# ESP32-H2 register map
Vendor: ESPRESSIF SYSTEMS (SHANGHAI) CO., LTD.; Series: ESP32 H-Series; File version: 11
CPU: RV32IMAC r0p0, little endian, no MPU, no FPU, 0 interrupt priority bits
Address unit: 32 bits
Registers are 32-bit, read-write, reset 0x0 unless marked. A register's access mark holds for its fields unless they carry their own. Offsets are from the block's base; [hi:lo] are bit positions; {n}, {i} and the like mark numbered series.

## GPIO_SD — Sigma-Delta Modulation
Base 0x60091F00
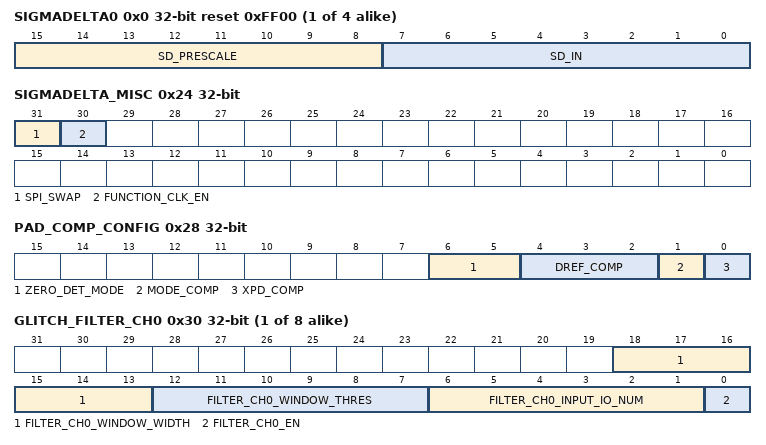
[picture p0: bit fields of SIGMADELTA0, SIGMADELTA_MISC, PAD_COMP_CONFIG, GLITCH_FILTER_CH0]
{0x0+4i} SIGMADELTA{i} (i=0..3) reset 0xFF00 — Duty Cycle Configure Register of SDM{i}
  [15:8] SD_PRESCALE — This field is used to set a divider value to divide APB clock.
  [7:0] SD_IN — This field is used to configure the duty cycle of sigma delta modulation output.
0x20 CLOCK_GATE — Clock Gating Configure Register
  [0] CLK_EN — Clock enable bit of configuration registers for sigma delta modulation.
0x24 SIGMADELTA_MISC — MISC Register
  [31] SPI_SWAP — Reserved.
  [30] FUNCTION_CLK_EN — Clock enable bit of sigma delta modulation.
0x28 PAD_COMP_CONFIG — PAD Compare configure Register
  [6:5] ZERO_DET_MODE — Zero Detect mode select.
  [4:2] DREF_COMP — internal reference voltage tuning bit. 0V to 0.7*VDDPST step 0.1*VDDPST.
  [1] MODE_COMP — 1 to enable external reference from PAD[0]. 0 to enable internal reference, meanwhile PAD[0] can be used as a regular GPIO.
  [0] XPD_COMP — Pad compare enable bit.
0x2C PAD_COMP_FILTER — Zero Detect filter Register
  [31:0] ZERO_DET_FILTER_CNT — Zero Detect filter cycle length
{0x30+4i} GLITCH_FILTER_CH{i} (i=0..7) — Glitch Filter Configure Register of Channel{i}
  [18:13] FILTER_CH0_WINDOW_WIDTH — Glitch Filter window width.
  [12:7] FILTER_CH0_WINDOW_THRES — Glitch Filter window threshold.
  [6:1] FILTER_CH0_INPUT_IO_NUM — Glitch Filter input io number.
  [0] FILTER_CH0_EN — Glitch Filter channel enable bit.
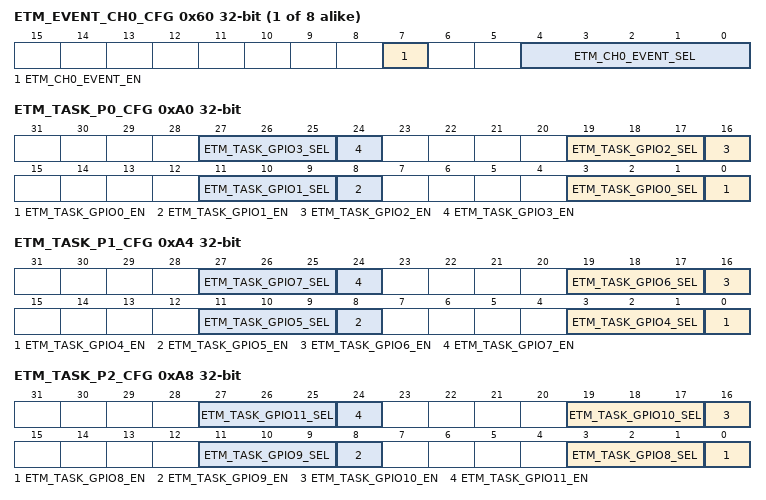
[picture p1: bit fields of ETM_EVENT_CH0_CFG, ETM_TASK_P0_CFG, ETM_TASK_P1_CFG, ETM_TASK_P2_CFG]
{0x60+4i} ETM_EVENT_CH{i}_CFG (i=0..7) — Etm Config register of Channel{i}
  [7] ETM_CH0_EVENT_EN — Etm event send enable bit.
  [4:0] ETM_CH0_EVENT_SEL — Etm event channel select gpio.
0xA0 ETM_TASK_P0_CFG — Etm Configure Register to decide which GPIO been chosen
  [8n+3:8n+1] ETM_TASK_GPIO{n}_SEL (n=0..3) — GPIO choose a etm task channel.
  [8n] ETM_TASK_GPIO{n}_EN (n=0..3) — Enable bit of GPIO response etm task.
0xA4 ETM_TASK_P1_CFG — Etm Configure Register to decide which GPIO been chosen
  [8n-29:8n-31] ETM_TASK_GPIO{n}_SEL (n=4..7) — GPIO choose a etm task channel.
  [8n-32] ETM_TASK_GPIO{n}_EN (n=4..7) — Enable bit of GPIO response etm task.
0xA8 ETM_TASK_P2_CFG — Etm Configure Register to decide which GPIO been chosen
  [8n-61:8n-63] ETM_TASK_GPIO{n}_SEL (n=8..11) — GPIO choose a etm task channel.
  [8n-64] ETM_TASK_GPIO{n}_EN (n=8..11) — Enable bit of GPIO response etm task.
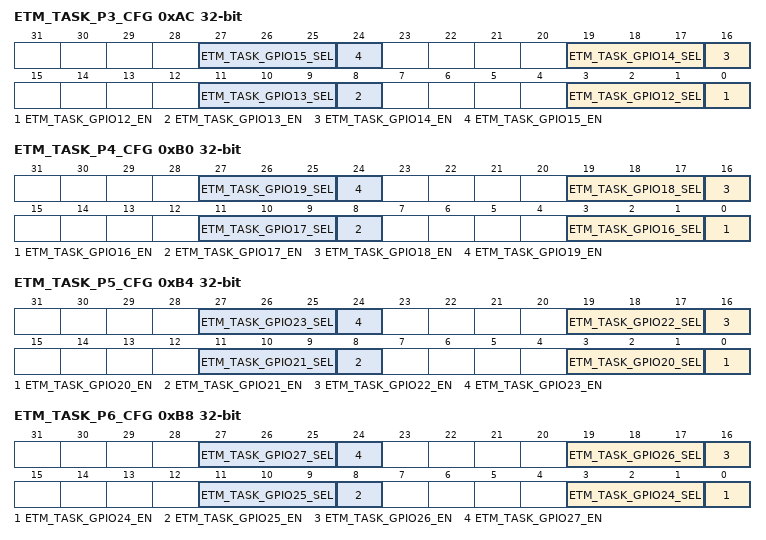
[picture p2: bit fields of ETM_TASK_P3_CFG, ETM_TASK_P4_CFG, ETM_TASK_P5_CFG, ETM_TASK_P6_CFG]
0xAC ETM_TASK_P3_CFG — Etm Configure Register to decide which GPIO been chosen
  [8n-93:8n-95] ETM_TASK_GPIO{n}_SEL (n=12..15) — GPIO choose a etm task channel.
  [8n-96] ETM_TASK_GPIO{n}_EN (n=12..15) — Enable bit of GPIO response etm task.
0xB0 ETM_TASK_P4_CFG — Etm Configure Register to decide which GPIO been chosen
  [8n-125:8n-127] ETM_TASK_GPIO{n}_SEL (n=16..19) — GPIO choose a etm task channel.
  [8n-128] ETM_TASK_GPIO{n}_EN (n=16..19) — Enable bit of GPIO response etm task.
0xB4 ETM_TASK_P5_CFG — Etm Configure Register to decide which GPIO been chosen
  [8n-157:8n-159] ETM_TASK_GPIO{n}_SEL (n=20..23) — GPIO choose a etm task channel.
  [8n-160] ETM_TASK_GPIO{n}_EN (n=20..23) — Enable bit of GPIO response etm task.
0xB8 ETM_TASK_P6_CFG — Etm Configure Register to decide which GPIO been chosen
  [8n-189:8n-191] ETM_TASK_GPIO{n}_SEL (n=24..27) — GPIO choose a etm task channel.
  [8n-192] ETM_TASK_GPIO{n}_EN (n=24..27) — Enable bit of GPIO response etm task.
0xE0 INT_RAW ro — GPIOSD interrupt raw register
  [0] PAD_COMP_INT_RAW — Pad compare raw interrupt
0xE4 INT_ST ro — GPIOSD interrupt masked register
  [0] PAD_COMP_INT_ST — Pad compare masked interrupt
0xE8 INT_ENA — GPIOSD interrupt enable register
  [0] PAD_COMP_INT_ENA — Pad compare interrupt enable
0xEC INT_CLR wo — GPIOSD interrupt clear register
  [0] PAD_COMP_INT_CLR — Pad compare interrupt clear
0xFC VERSION reset 0x2208120 — Version Control Register
  [27:0] GPIO_SD_DATE — Version control register.
